VERSION ""

NS_ :

BS_:

BU_: SECU ES DCDC

BO_ 1536 NDCDCCtrl: 8 SECU
 SG_ BoostCoilOffRequested : 3|2@0+ (1,0) [0|3] "-" DCDC

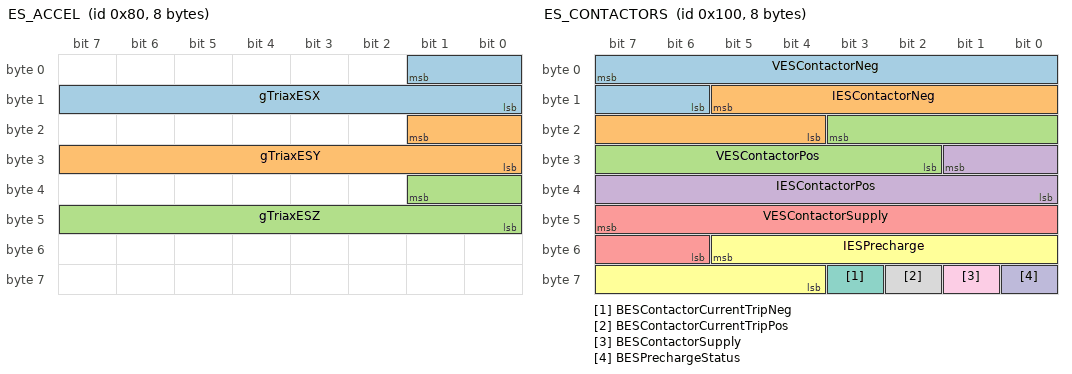
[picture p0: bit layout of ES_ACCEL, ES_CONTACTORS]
BO_ 128 ES_ACCEL: 8 ES
 SG_ gTriaxESX : 1|10@0- (0.015625,0) [-8|8] "G" SECU
 SG_ gTriaxESY : 17|10@0- (0.015625,0) [-8|8] "G" SECU
 SG_ gTriaxESZ : 33|10@0- (0.015625,0) [-8|8] "G" SECU

BO_ 256 ES_CONTACTORS: 8 ES
 SG_ VESContactorNeg : 7|10@0+ (1.58019822006473E-02,0) [0|16.1812297734628] "V" SECU
 SG_ IESContactorNeg : 13|10@0+ (1.220703125,0) [0|1250] "mA" SECU
 SG_ VESContactorPos : 19|10@0+ (1.58019822006473E-02,0) [0|16.1812297734628] "V" SECU
 SG_ IESContactorPos : 25|10@0+ (1.220703125,0) [0|1250] "mA" SECU
 SG_ VESContactorSupply : 47|10@0+ (1.52717752659574E-02,0) [0|15.6382978723404] "V" SECU
 SG_ IESPrecharge : 53|10@0+ (0.406901041666667,0) [0|416.666666666667] "mA" SECU
 SG_ BESContactorCurrentTripNeg : 59|1@0+ (1,0) [0|1] "-" SECU
 SG_ BESContactorCurrentTripPos : 58|1@0+ (1,0) [0|1] "-" SECU
 SG_ BESContactorSupply : 57|1@0+ (1,0) [0|1] "-" SECU
 SG_ BESPrechargeStatus : 56|1@0+ (1,0) [0|1] "-" SECU

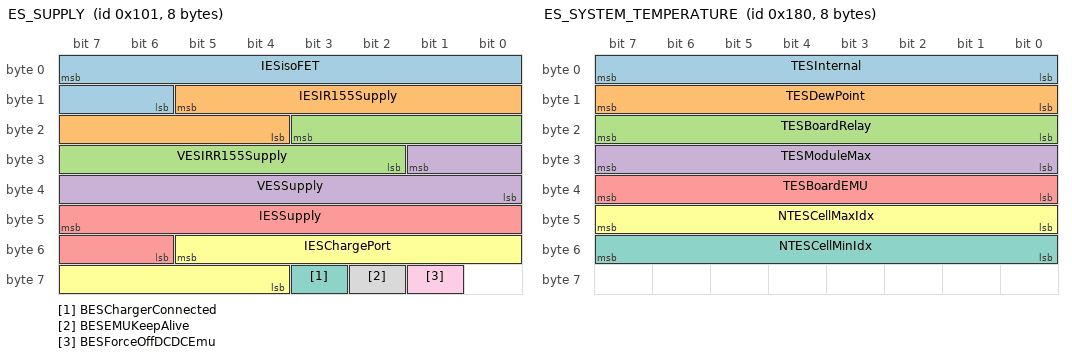
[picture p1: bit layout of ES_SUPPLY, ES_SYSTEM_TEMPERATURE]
BO_ 257 ES_SUPPLY: 8 ES
 SG_ IESisoFET : 7|10@0+ (0.406901041666667,0) [0|416.666666666667] "mA" SECU
 SG_ IESIR155Supply : 13|10@0+ (0.813802083333333,0) [0|833.333333333333] "mA" SECU
 SG_ VESIRR155Supply : 19|10@0+ (1.52717752659574E-02,0) [0|15.6382978723404] "V" SECU
 SG_ VESSupply : 25|10@0+ (1.52717752659574E-02,0) [0|15.6382978723404] "V" SECU
 SG_ IESSupply : 47|10@0+ (0.813802083333333,0) [0|833.333333333333] "mA" SECU
 SG_ IESChargePort : 53|10@0+ (0.406901041666667,0) [0|416.666666666667] "mA" SECU
 SG_ BESChargerConnected : 59|1@0+ (1,0) [0|1] "-" SECU
 SG_ BESEMUKeepAlive : 58|1@0+ (1,0) [0|1] "-" SECU
 SG_ BESForceOffDCDCEmu : 57|1@0+ (1,0) [0|1] "-" SECU

BO_ 384 ES_SYSTEM_TEMPERATURE: 8 ES
 SG_ TESInternal : 7|8@0+ (1,-40) [-40|210] "degreesC" SECU
 SG_ TESDewPoint : 15|8@0+ (1,-120) [-120|135] "degreesC" SECU
 SG_ TESBoardRelay : 23|8@0+ (1,-40) [-40|210] "degreesC" SECU
 SG_ TESModuleMax : 31|8@0+ (1,-40) [-40|210] "degreesC" SECU
 SG_ TESBoardEMU : 39|8@0+ (1,-40) [-40|210] "degreesC" SECU
 SG_ NTESCellMaxIdx : 47|8@0+ (1,0) [0|255] "-" SECU
 SG_ NTESCellMinIdx : 55|8@0+ (1,0) [0|255] "-" SECU

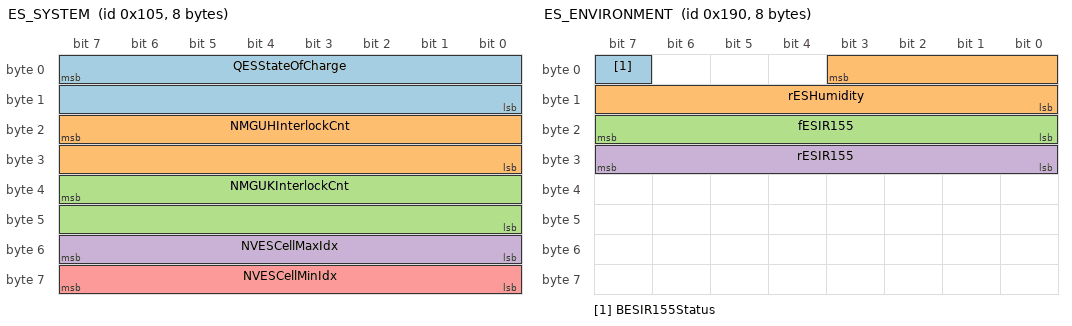
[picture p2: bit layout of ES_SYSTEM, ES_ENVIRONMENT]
BO_ 261 ES_SYSTEM: 8 ES
 SG_ QESStateOfCharge : 7|16@0- (1,0) [-30000|30000] "mAh" SECU
 SG_ NMGUHInterlockCnt : 23|16@0+ (1,0) [0|65535] "-" SECU
 SG_ NMGUKInterlockCnt : 39|16@0+ (1,0) [0|65535] "-" SECU
 SG_ NVESCellMaxIdx : 55|8@0+ (1,0) [0|255] "-" SECU
 SG_ NVESCellMinIdx : 63|8@0+ (1,0) [0|255] "-" SECU

BO_ 400 ES_ENVIRONMENT: 8 ES
 SG_ BESIR155Status : 7|1@0+ (1,0) [0|1] "-" SECU
 SG_ rESHumidity : 3|12@0+ (0.5,0) [0|100] "%" SECU
 SG_ fESIR155 : 23|8@0+ (1,0) [0|100] "Hz" SECU
 SG_ rESIR155 : 31|8@0+ (1,0) [0|100] "%" SECU

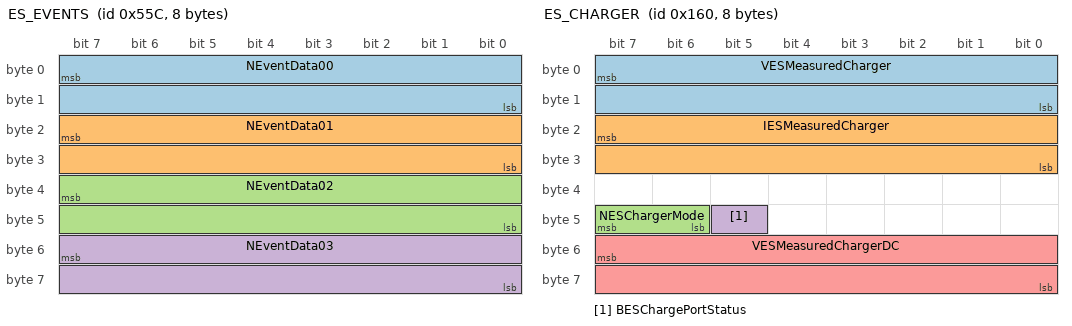
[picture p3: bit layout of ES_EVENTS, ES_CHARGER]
BO_ 1372 ES_EVENTS: 8 ES
 SG_ NEventData00 : 7|16@0+ (1,0) [0|65535] "-" SECU
 SG_ NEventData01 : 23|16@0+ (1,0) [0|65535] "-" SECU
 SG_ NEventData02 : 39|16@0+ (1,0) [0|65535] "-" SECU
 SG_ NEventData03 : 55|16@0+ (1,0) [0|65535] "-" SECU

BO_ 272 ES_STATUS: 8 ES
 SG_ muxEsStatus M : 7|8@0+ (1,0) [0|12] "-" SECU
 SG_ NESResetCount m0 : 15|8@0+ (1,0) [0|255] "-" SECU
 SG_ NESSerialNo m1 : 15|8@0+ (1,0) [0|255] "-" SECU
 SG_ NESCAN01BusState m2 : 15|2@0+ (1,0) [0|3] "-" SECU
 SG_ BQESStateOfChargeReset m3 : 15|1@0+ (1,0) [0|1] "-" SECU
 SG_ NESModuleIdxOpenWire m4 : 15|5@0+ (1,0) [0|20] "-" SECU
 SG_ NESModuleIdxComms m5 : 15|5@0+ (1,0) [0|20] "-" SECU
 SG_ NESModuleIdxFault m6 : 15|5@0+ (1,0) [0|20] "-" SECU
 SG_ NESCellsBalanced m7 : 15|8@0+ (1,0) [0|240] "-" SECU
 SG_ NESModuleADCStoppedCount m8 : 15|8@0+ (1,0) [0|255] "-" SECU
 SG_ NEMUSerialNumber m9 : 15|16@0+ (1,0) [0|65535] "-" SECU
 SG_ QESLastSOCReset m10 : 15|16@0- (1,0) [-30000|30000] "mAh" SECU
 SG_ QESLastBalance m11 : 15|16@0- (1,0) [-30000|30000] "mAh" SECU
 SG_ NESCAN02BusState m2 : 13|2@0+ (1,0) [0|3] "-" SECU
 SG_ BESEthernetConnected m3 : 12|1@0+ (1,0) [0|1] "-" SECU
 SG_ NESCAN03BusState m2 : 11|2@0+ (1,0) [0|3] "-" SECU
 SG_ NESCANChargerBusState m2 : 9|2@0+ (1,0) [0|3] "-" SECU
 SG_ NESCAN01BusOffCount m0 : 23|16@0+ (1,0) [0|65535] "-" SECU
 SG_ NESCAN02BusOffCount m1 : 23|16@0+ (1,0) [0|65535] "-" SECU
 SG_ NESCAN03BusOffCount m2 : 23|16@0+ (1,0) [0|65535] "-" SECU
 SG_ NESCANChargerBusOffCount m3 : 23|16@0+ (1,0) [0|65535] "-" SECU
 SG_ NESCANChargerTxMsgCount m4 : 23|16@0+ (1,0) [0|65535] "-" SECU
 SG_ NESCAN02RxMsgCount m5 : 23|16@0+ (1,0) [0|65535] "-" SECU
 SG_ NESCAN03TxMsgCount m6 : 23|16@0+ (1,0) [0|65535] "-" SECU
 SG_ NESOpenWire m7 : 23|16@0+ (1,0) [0|65535] "-" SECU
 SG_ NESResetReason m8 : 23|16@0+ (1,0) [0|65535] "-" SECU
 SG_ EESPrecharge m12 : 23|16@0+ (1,0) [0|65535] "J" SECU
 SG_ NESActiveResetCount m9 : 31|8@0+ (1,0) [0|255] "-" SECU
 SG_ NESCAN01ErrorCount m0 : 39|16@0+ (1,0) [0|65535] "-" SECU
 SG_ NESCAN02ErrorCount m1 : 39|16@0+ (1,0) [0|65535] "-" SECU
 SG_ NESCAN03ErrorCount m2 : 39|16@0+ (1,0) [0|65535] "-" SECU
 SG_ NESCANChargerErrorCount m3 : 39|16@0+ (1,0) [0|65535] "-" SECU
 SG_ NESCAN01RxMsgCount m4 : 39|16@0+ (1,0) [0|65535] "-" SECU
 SG_ NESCAN02TxMsgCount m5 : 39|16@0+ (1,0) [0|65535] "-" SECU
 SG_ NESModuleCommsErrors m7 : 39|16@0+ (1,0) [0|65535] "-" SECU
 SG_ NESSoftwareVersion m8 : 39|32@0+ (1,0) [0|4294967295] "-" SECU
 SG_ QESStateOfChargeOffset m9 : 39|16@0- (1,0) [-30000|30000] "mAh" SECU
 SG_ tESLastBalance m10 : 39|32@0+ (1,0) [0|4294967295] "s" SECU
 SG_ tESLastSOCReset m11 : 39|32@0+ (1,0) [0|4294967295] "s" SECU
 SG_ EESPrechargeMax m12 : 39|16@0+ (1,0) [0|65535] "J" SECU
 SG_ VESRef m0 : 55|16@0+ (0.0048828125,0) [0|5] "V" SECU
 SG_ NESEthernetTx m1 : 55|16@0+ (1,0) [0|65535] "-" SECU
 SG_ NESEthernetRx m2 : 55|16@0+ (1,0) [0|65535] "-" SECU
 SG_ NESCANChargerRxMsgCount m3 : 55|16@0+ (1,0) [0|65535] "-" SECU
 SG_ NESCAN01TxMsgCount m4 : 55|16@0+ (1,0) [0|65535] "-" SECU
 SG_ NESCAN03RxMsgCount m5 : 55|16@0+ (1,0) [0|65535] "-" SECU
 SG_ NESModuleFaultCounter m6 : 55|8@0+ (1,0) [0|255] "-" SECU
 SG_ NESCellsBalancing m7 : 55|8@0+ (1,0) [0|240] "-" SECU
 SG_ QESStateOfChargeIntegral m9 : 55|16@0- (1,0) [-30000|30000] "mAh" SECU
 SG_ VESPrechargeMin m12 : 55|16@0+ (0.036,0) [-1179.648|1179.63] "V" SECU
 SG_ NESModuleADCRangeCount m6 : 63|8@0+ (1,0) [0|255] "-" SECU
 SG_ NESModuleMismatchCount m7 : 63|8@0+ (1,0) [0|255] "-" SECU

BO_ 352 ES_CHARGER: 8 ES
 SG_ VESMeasuredCharger : 7|16@0- (0.036,0) [-1179.648|1179.63] "V" SECU
 SG_ IESMeasuredCharger : 23|16@0- (0.001,0) [0|10] "A" SECU
 SG_ NESChargerMode : 47|2@0+ (1,0) [0|3] "-" SECU
 SG_ BESChargePortStatus : 45|1@0+ (1,0) [0|1] "-" SECU
 SG_ VESMeasuredChargerDC : 55|16@0+ (0.02992,-980.41856) [-980.41856|980.38864] "V" SECU

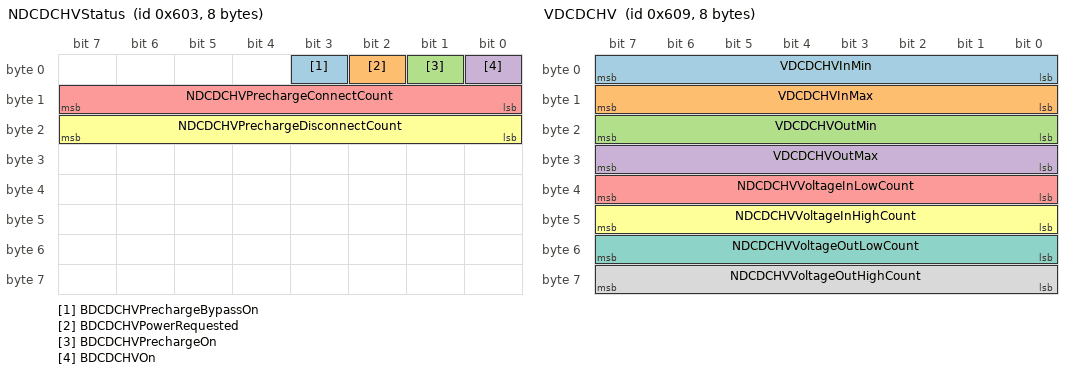
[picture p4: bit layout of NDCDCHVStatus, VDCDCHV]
BO_ 1539 NDCDCHVStatus: 8 DCDC
 SG_ BDCDCHVPrechargeBypassOn : 3|1@0+ (1,0) [0|1] "-" SECU
 SG_ BDCDCHVPowerRequested : 2|1@0+ (1,0) [0|1] "-" SECU
 SG_ BDCDCHVPrechargeOn : 1|1@0+ (1,0) [0|1] "-" SECU
 SG_ BDCDCHVOn : 0|1@0+ (1,0) [0|1] "-" SECU
 SG_ NDCDCHVPrechargeConnectCount : 15|8@0+ (1,0) [0|255] "-" SECU
 SG_ NDCDCHVPrechargeDisconnectCount : 23|8@0+ (1,0) [0|255] "-" SECU

BO_ 1537 NDCDCPLVStatus: 8 DCDC
 SG_ BDCDCPLVBackupBatteryChargerIdle : 7|1@0+ (1,0) [0|1] "-" SECU
 SG_ BDCDCPLVBackupBatteryChargerOn : 6|1@0+ (1,0) [0|1] "-" SECU
 SG_ BDCDCPLVEMUOutputOn : 5|1@0+ (1,0) [0|1] "-" SECU
 SG_ BDCDCPLVCoilOutputOn : 4|1@0+ (1,0) [0|1] "-" SECU
 SG_ BDCDCPLVBoostOutputOn : 3|1@0+ (1,0) [0|1] "-" SECU
 SG_ BDCDCPLVMainConverterOn : 2|1@0+ (1,0) [0|1] "-" ES,SECU
 SG_ BDCDCPLVUmbilicalAvailable : 1|1@0+ (1,0) [0|1] "-" SECU
 SG_ BDCDCPLVMainOutputOn : 0|1@0+ (1,0) [0|1] "-" SECU
 SG_ BDCDCPLVKeepAliveEMU : 15|1@0+ (1,0) [0|1] "-" SECU
 SG_ BDCDCPLVForceOffEMU : 14|1@0+ (1,0) [0|1] "-" SECU
 SG_ BDCDCPLVKeepAliveTAG : 13|1@0+ (1,0) [0|1] "-" SECU
 SG_ BDCDCPLVEnableSwitch : 12|1@0+ (1,0) [0|1] "-" SECU
 SG_ BDCDCPLVKeepAliveSLVC : 11|1@0+ (1,0) [0|1] "-" SECU
 SG_ BDCDCPLVKeepAliveHVC : 10|1@0+ (1,0) [0|1] "-" SECU
 SG_ BDCDCPLVEnableCommSLVC : 9|1@0+ (1,0) [0|1] "-" SECU
 SG_ BDCDCPLVEnableCommHVC : 8|1@0+ (1,0) [0|1] "-" SECU
 SG_ NDCDCPLVEnableSwitchFallCount : 23|4@0+ (1,0) [0|15] "-" SECU
 SG_ NDCDCPLVEnableSwitchRiseCount : 19|4@0+ (1,0) [0|15] "-" SECU
 SG_ NDCDCPLVKeepAliveTAGFallCount : 31|4@0+ (1,0) [0|15] "-" SECU
 SG_ NDCDCPLVKeepAliveTAGRiseCount : 27|4@0+ (1,0) [0|15] "-" SECU
 SG_ NDCDCPLVApplicationEntryCount : 39|8@0+ (1,0) [0|255] "-" SECU
 SG_ NDCDCPLVApplicationExitCount : 47|8@0+ (1,0) [0|255] "-" SECU

BO_ 1542 TDCDCHV: 8 DCDC
 SG_ TDCDCHVCPU : 7|8@0+ (1,0) [0|255] "degreesC" SECU
 SG_ TDCDCHVPCB : 15|8@0+ (1,0) [0|255] "degreesC" SECU

BO_ 1545 VDCDCHV: 8 DCDC
 SG_ VDCDCHVInMin : 7|8@0+ (3.9,0) [0|994.5] "V" SECU
 SG_ VDCDCHVInMax : 15|8@0+ (3.9,0) [0|994.5] "V" SECU
 SG_ VDCDCHVOutMin : 23|8@0+ (3,0) [0|765] "V" SECU
 SG_ VDCDCHVOutMax : 31|8@0+ (3,0) [0|765] "V" SECU
 SG_ NDCDCHVVoltageInLowCount : 39|8@0+ (1,0) [0|255] "-" SECU
 SG_ NDCDCHVVoltageInHighCount : 47|8@0+ (1,0) [0|255] "-" SECU
 SG_ NDCDCHVVoltageOutLowCount : 55|8@0+ (1,0) [0|255] "-" SECU
 SG_ NDCDCHVVoltageOutHighCount : 63|8@0+ (1,0) [0|255] "-" SECU

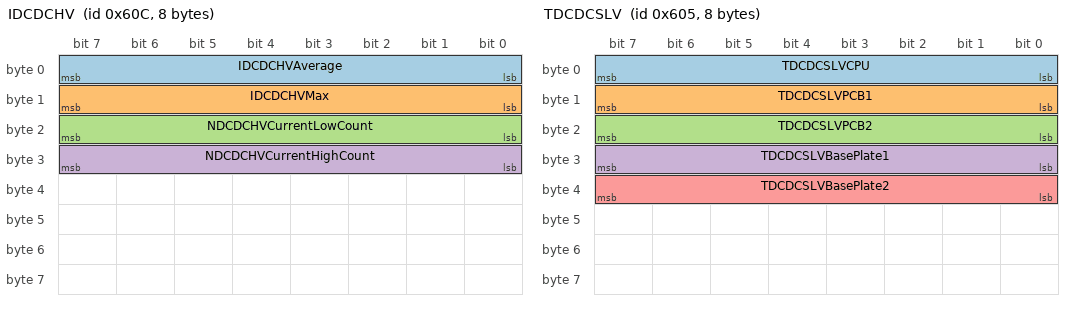
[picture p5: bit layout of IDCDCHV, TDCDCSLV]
BO_ 1548 IDCDCHV: 8 DCDC
 SG_ IDCDCHVAverage : 7|8@0+ (0.032,0) [0|8.16] "A" SECU
 SG_ IDCDCHVMax : 15|8@0+ (0.032,0) [0|8.16] "A" SECU
 SG_ NDCDCHVCurrentLowCount : 23|8@0+ (1,0) [0|255] "-" SECU
 SG_ NDCDCHVCurrentHighCount : 31|8@0+ (1,0) [0|255] "-" SECU

BO_ 1541 TDCDCSLV: 8 DCDC
 SG_ TDCDCSLVCPU : 7|8@0+ (1,0) [0|255] "degreesC" SECU
 SG_ TDCDCSLVPCB1 : 15|8@0+ (1,0) [0|255] "degreesC" SECU
 SG_ TDCDCSLVPCB2 : 23|8@0+ (1,0) [0|255] "degreesC" SECU
 SG_ TDCDCSLVBasePlate1 : 31|8@0+ (1,0) [0|255] "degreesC" SECU
 SG_ TDCDCSLVBasePlate2 : 39|8@0+ (1,0) [0|255] "degreesC" SECU

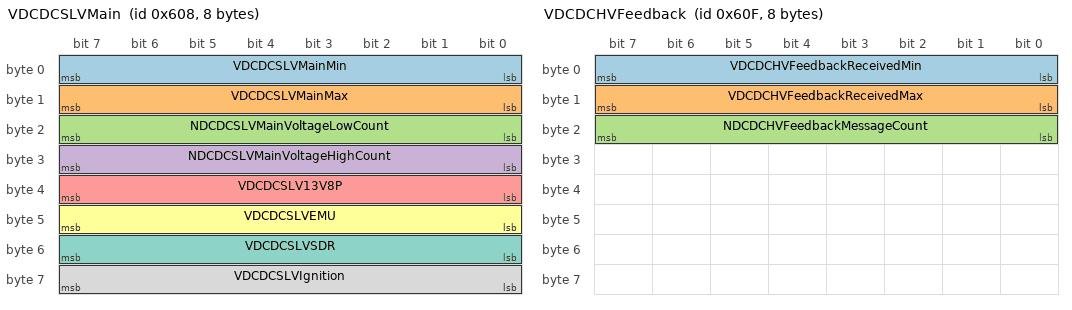
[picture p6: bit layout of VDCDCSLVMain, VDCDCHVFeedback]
BO_ 1544 VDCDCSLVMain: 8 DCDC
 SG_ VDCDCSLVMainMin : 7|8@0+ (0.075,0) [0|19.125] "V" SECU
 SG_ VDCDCSLVMainMax : 15|8@0+ (0.075,0) [0|19.125] "V" SECU
 SG_ NDCDCSLVMainVoltageLowCount : 23|8@0+ (1,0) [0|255] "-" SECU
 SG_ NDCDCSLVMainVoltageHighCount : 31|8@0+ (1,0) [0|255] "-" SECU
 SG_ VDCDCSLV13V8P : 39|8@0+ (0.075,0) [0|19.125] "V" SECU
 SG_ VDCDCSLVEMU : 47|8@0+ (0.075,0) [0|19.125] "V" SECU
 SG_ VDCDCSLVSDR : 55|8@0+ (0.075,0) [0|19.125] "V" SECU
 SG_ VDCDCSLVIgnition : 63|8@0+ (0.075,0) [0|19.125] "V" SECU

BO_ 1551 VDCDCHVFeedback: 8 DCDC
 SG_ VDCDCHVFeedbackReceivedMin : 7|8@0+ (0.234,0) [0|59.67] "V" SECU
 SG_ VDCDCHVFeedbackReceivedMax : 15|8@0+ (0.234,0) [0|59.67] "V" SECU
 SG_ NDCDCHVFeedbackMessageCount : 23|8@0+ (1,0) [0|255] "-" SECU

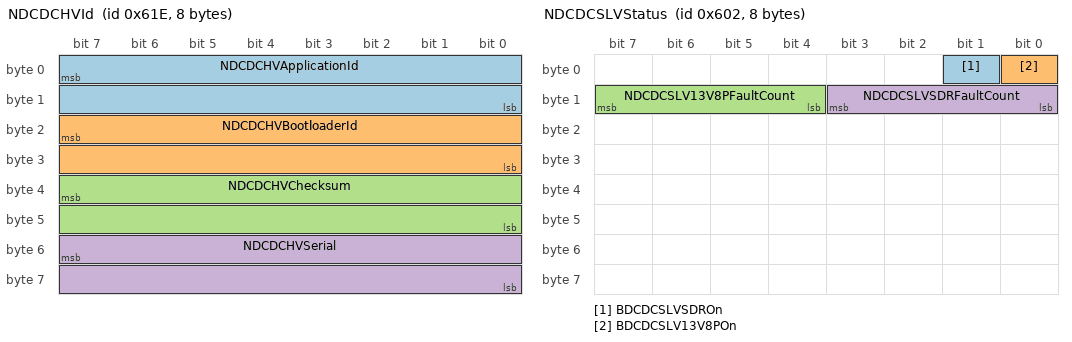
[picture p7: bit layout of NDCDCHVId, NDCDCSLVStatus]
BO_ 1566 NDCDCHVId: 8 DCDC
 SG_ NDCDCHVApplicationId : 7|16@0+ (1,0) [0|65535] "-" SECU
 SG_ NDCDCHVBootloaderId : 23|16@0+ (1,0) [0|65535] "-" SECU
 SG_ NDCDCHVChecksum : 39|16@0+ (1,0) [0|65535] "-" SECU
 SG_ NDCDCHVSerial : 55|16@0+ (1,0) [0|65535] "-" SECU

BO_ 1538 NDCDCSLVStatus: 8 DCDC
 SG_ BDCDCSLVSDROn : 1|1@0+ (1,0) [0|1] "-" SECU
 SG_ BDCDCSLV13V8POn : 0|1@0+ (1,0) [0|1] "-" SECU
 SG_ NDCDCSLV13V8PFaultCount : 15|4@0+ (1,0) [0|15] "-" SECU
 SG_ NDCDCSLVSDRFaultCount : 11|4@0+ (1,0) [0|15] "-" SECU

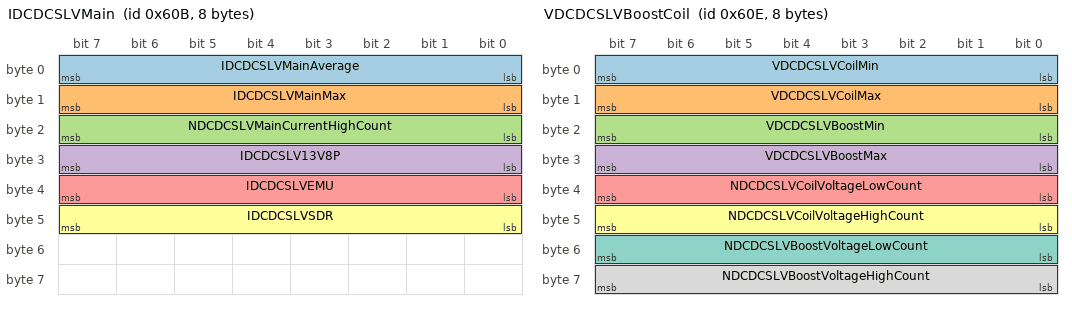
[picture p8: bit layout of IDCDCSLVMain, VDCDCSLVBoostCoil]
BO_ 1547 IDCDCSLVMain: 8 DCDC
 SG_ IDCDCSLVMainAverage : 7|8@0+ (0.334,0) [0|85.17] "A" SECU
 SG_ IDCDCSLVMainMax : 15|8@0+ (0.334,0) [0|85.17] "A" SECU
 SG_ NDCDCSLVMainCurrentHighCount : 23|8@0+ (1,0) [0|255] "-" SECU
 SG_ IDCDCSLV13V8P : 31|8@0+ (0.1,0) [0|25.5] "A" SECU
 SG_ IDCDCSLVEMU : 39|8@0+ (0.01567,0) [0|3.99585] "A" SECU
 SG_ IDCDCSLVSDR : 47|8@0+ (0.02745,0) [0|6.99975] "A" SECU

BO_ 1550 VDCDCSLVBoostCoil: 8 DCDC
 SG_ VDCDCSLVCoilMin : 7|8@0+ (0.234,0) [0|59.67] "V" SECU
 SG_ VDCDCSLVCoilMax : 15|8@0+ (0.234,0) [0|59.67] "V" SECU
 SG_ VDCDCSLVBoostMin : 23|8@0+ (0.441,0) [0|112.455] "V" SECU
 SG_ VDCDCSLVBoostMax : 31|8@0+ (0.441,0) [0|112.455] "V" SECU
 SG_ NDCDCSLVCoilVoltageLowCount : 39|8@0+ (1,0) [0|255] "-" SECU
 SG_ NDCDCSLVCoilVoltageHighCount : 47|8@0+ (1,0) [0|255] "-" SECU
 SG_ NDCDCSLVBoostVoltageLowCount : 55|8@0+ (1,0) [0|255] "-" SECU
 SG_ NDCDCSLVBoostVoltageHighCount : 63|8@0+ (1,0) [0|255] "-" SECU

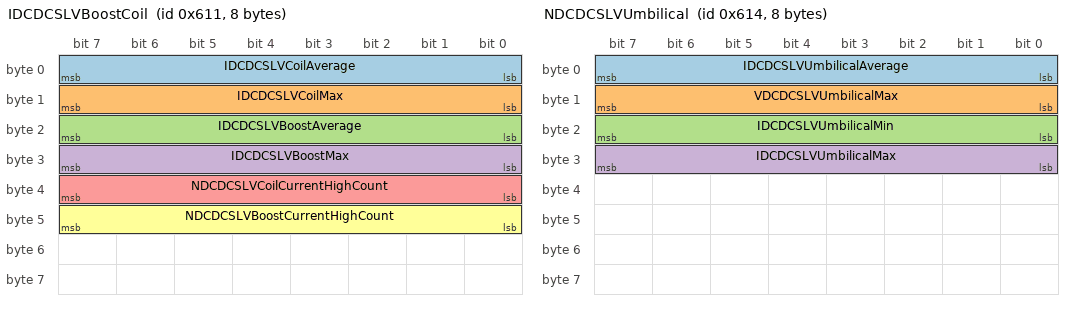
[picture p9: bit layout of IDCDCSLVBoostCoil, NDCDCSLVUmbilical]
BO_ 1553 IDCDCSLVBoostCoil: 8 DCDC
 SG_ IDCDCSLVCoilAverage : 7|8@0+ (0.095,0) [0|24.225] "A" SECU
 SG_ IDCDCSLVCoilMax : 15|8@0+ (0.095,0) [0|24.225] "A" SECU
 SG_ IDCDCSLVBoostAverage : 23|8@0+ (0.02745,0) [0|6.99975] "A" SECU
 SG_ IDCDCSLVBoostMax : 31|8@0+ (0.02745,0) [0|6.99975] "A" SECU
 SG_ NDCDCSLVCoilCurrentHighCount : 39|8@0+ (1,0) [0|255] "-" SECU
 SG_ NDCDCSLVBoostCurrentHighCount : 47|8@0+ (1,0) [0|255] "-" SECU

BO_ 1556 NDCDCSLVUmbilical: 8 DCDC
 SG_ IDCDCSLVUmbilicalAverage : 7|8@0+ (0.075,0) [0|19.125] "V" SECU
 SG_ VDCDCSLVUmbilicalMax : 15|8@0+ (0.075,0) [0|19.125] "V" SECU
 SG_ IDCDCSLVUmbilicalMin : 23|8@0+ (0.118,0) [0|30.09] "A" SECU
 SG_ IDCDCSLVUmbilicalMax : 31|8@0+ (0.118,0) [0|30.09] "A" SECU

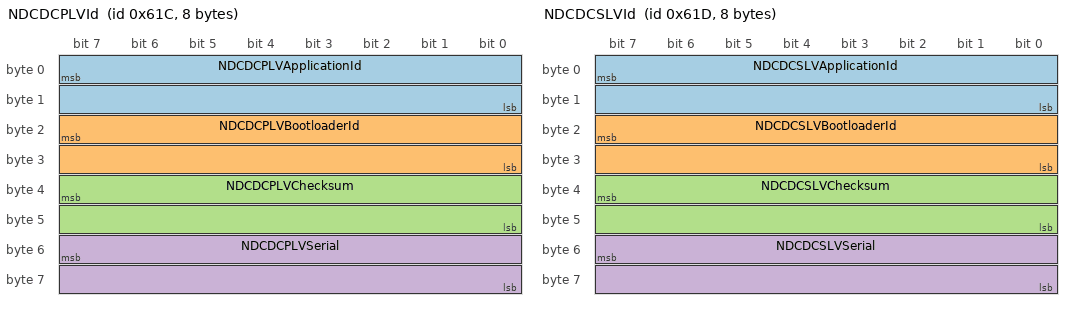
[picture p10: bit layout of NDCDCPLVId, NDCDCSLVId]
BO_ 1564 NDCDCPLVId: 8 DCDC
 SG_ NDCDCPLVApplicationId : 7|16@0+ (1,0) [0|65535] "-" SECU
 SG_ NDCDCPLVBootloaderId : 23|16@0+ (1,0) [0|65535] "-" SECU
 SG_ NDCDCPLVChecksum : 39|16@0+ (1,0) [0|65535] "-" SECU
 SG_ NDCDCPLVSerial : 55|16@0+ (1,0) [0|65535] "-" SECU

BO_ 1565 NDCDCSLVId: 8 DCDC
 SG_ NDCDCSLVApplicationId : 7|16@0+ (1,0) [0|65535] "-" SECU
 SG_ NDCDCSLVBootloaderId : 23|16@0+ (1,0) [0|65535] "-" SECU
 SG_ NDCDCSLVChecksum : 39|16@0+ (1,0) [0|65535] "-" SECU
 SG_ NDCDCSLVSerial : 55|16@0+ (1,0) [0|65535] "-" SECU

BO_ 1543 VDCDCPLV: 8 DCDC
 SG_ VDCDCPLVBackupBattery : 7|8@0+ (0.02588,0) [0|6.5994] "V" SECU

BO_ 1540 IDCDCPLVBuckLoadUnbalance: 8 DCDC
 SG_ IDCDCPLVBuckLoadUnbalance : 7|8@0+ (0.161,0) [0|41.055] "A" SECU

CM_ SG_ 128 gTriaxESX "ES internal triax X axis acceleration";
CM_ SG_ 128 gTriaxESY "ES internal triax Y axis acceleration";
CM_ SG_ 128 gTriaxESZ "ES internal triax Z axis acceleration";
CM_ SG_ 256 VESContactorNeg "Voltage across the negative contactor coil voltage";
CM_ SG_ 256 IESContactorNeg "Negative contactor coil current";
CM_ SG_ 256 VESContactorPos "Voltage across the positive contactor coil voltage";
CM_ SG_ 256 IESContactorPos "Positive contactor coil current";
CM_ SG_ 256 VESContactorSupply "ES contactor supply voltage";
CM_ SG_ 256 IESPrecharge "Precharge relay coil current";
CM_ SG_ 256 BESContactorCurrentTripNeg "Negative contactor drive circuit in error flag";
CM_ SG_ 256 BESContactorCurrentTripPos "Positive contactor drive circuit in error flag";
CM_ SG_ 256 BESContactorSupply "Set when the VESContactorSupply is present";
CM_ SG_ 256 BESPrechargeStatus "Status of the pre-charge relay";
CM_ SG_ 257 IESisoFET "IsoFET drive current";
CM_ SG_ 257 IESIR155Supply "Bender supply current";
CM_ SG_ 257 VESIRR155Supply "12V supply voltage to the IR155";
CM_ SG_ 257 VESSupply "Energy store 12V supply voltage";
CM_ SG_ 257 IESSupply "ES 12V supply current";
CM_ SG_ 257 IESChargePort "Charge port relay coil current";
CM_ SG_ 257 BESChargerConnected "Set to indicate that the off-car charger is connected to the charger CAN port";
CM_ SG_ 257 BESEMUKeepAlive "Flag indicating that the EMU wishes to be kept alive in P0";
CM_ SG_ 257 BESForceOffDCDCEmu "Command to force the HV supply to the DC-DC converter off";
CM_ SG_ 384 TESInternal "Ambient temperature inside the energy store";
CM_ SG_ 384 TESDewPoint "Measured dew point within the ES";
CM_ SG_ 384 TESBoardRelay "Board temperature of the EMU HV relay board";
CM_ SG_ 384 TESModuleMax "Max ES module board temperature";
CM_ SG_ 384 TESBoardEMU "Board temperature of the EMU";
CM_ SG_ 384 NTESCellMaxIdx "Index of the highest cell temperature in the pack";
CM_ SG_ 384 NTESCellMinIdx "Index of the lowest cell temperature in the pack";
CM_ SG_ 261 QESStateOfCharge "ES state of discharge in mAh";
CM_ SG_ 261 NMGUHInterlockCnt "Count of the transitions in the ES MGU-H HVIL input";
CM_ SG_ 261 NMGUKInterlockCnt "Count of the transitions in the ES MGU-K HVIL input";
CM_ SG_ 261 NVESCellMaxIdx "Index of the cell with the highest voltage in the pack";
CM_ SG_ 261 NVESCellMinIdx "Index of the cell with the lowest voltage in the pack";
CM_ SG_ 400 BESIR155Status "Fault status of the Bender IR155 board";
CM_ SG_ 400 rESHumidity "Relative humidity within the ES";
CM_ SG_ 400 fESIR155 "Measured output frequency of the Bender IR155 board";
CM_ SG_ 400 rESIR155 "Measured output duty cycle of the Bender IR155 board";
CM_ SG_ 1372 NEventData00 "Event data word 0";
CM_ SG_ 1372 NEventData01 "Event data word 1";
CM_ SG_ 1372 NEventData02 "Event data word 2";
CM_ SG_ 1372 NEventData03 "Event data word 3";
CM_ SG_ 272 NESResetCount "Number of EMU processor resets";
CM_ SG_ 272 NESCAN01BusOffCount "ES CAN bus 01 bus off count";
CM_ SG_ 272 NESCAN01ErrorCount "ES CAN bus 01 error count";
CM_ SG_ 272 VESRef "2.5V reference voltage on the EMU board";
CM_ SG_ 272 NESSerialNo "ES Serial number";
CM_ SG_ 272 NESCAN02BusOffCount "ES CAN bus 02 bus off count";
CM_ SG_ 272 NESCAN02ErrorCount "ES CAN bus 02 error count";
CM_ SG_ 272 NESEthernetTx "Ethernet Frames Transmitted OK Counter";
CM_ SG_ 272 NESCAN01BusState "ES CAN bus 01 bus state (Active, Passive, Off)";
CM_ SG_ 272 NESCAN02BusState "ES CAN bus 02 bus state (Active, Passive, Off)";
CM_ SG_ 272 NESCAN03BusState "ES CAN bus 03 bus state (Active, Passive, Off)";
CM_ SG_ 272 NESCANChargerBusState "ES charge CAN bus state (Active, Passive, Off)";
CM_ SG_ 272 NESCAN03BusOffCount "ES CAN bus 03 bus off count";
CM_ SG_ 272 NESCAN03ErrorCount "ES CAN bus 03 error count";
CM_ SG_ 272 NESEthernetRx "Ethernet Frames Received OK Counter";
CM_ SG_ 272 BQESStateOfChargeReset "Flag indicating that the SOC has been reset at startup";
CM_ SG_ 272 BESEthernetConnected "Status of the Ethernet connection";
CM_ SG_ 272 NESCANChargerBusOffCount "ES charger CAN bus off count";
CM_ SG_ 272 NESCANChargerErrorCount "ES charger CAN bus error count";
CM_ SG_ 272 NESCANChargerRxMsgCount "ES charge CAN bus received message count";
CM_ SG_ 272 NESModuleIdxOpenWire "Index of the module with the most open wire counts";
CM_ SG_ 272 NESCANChargerTxMsgCount "ES charger CAN bus transmitted message count";
CM_ SG_ 272 NESCAN01RxMsgCount "ES CAN bus 01 received message count";
CM_ SG_ 272 NESCAN01TxMsgCount "ES CAN bus 01 transmitted message count";
CM_ SG_ 272 NESModuleIdxComms "Index of the module with the most comms errors";
CM_ SG_ 272 NESCAN02RxMsgCount "ES CAN bus 02 received message count";
CM_ SG_ 272 NESCAN02TxMsgCount "ES CAN bus 02 transmitted message count";
CM_ SG_ 272 NESCAN03RxMsgCount "ES CAN bus 03 received message count";
CM_ SG_ 272 NESModuleIdxFault "Index of the module with the most self test errors";
CM_ SG_ 272 NESCAN03TxMsgCount "ES CAN bus 03 transmitted message count";
CM_ SG_ 272 NESModuleFaultCounter "Total number of self test failures";
CM_ SG_ 272 NESModuleADCRangeCount "Number of mismatches ADC range errors";
CM_ SG_ 272 NESCellsBalanced "Number of cell that are balanced";
CM_ SG_ 272 NESOpenWire "Count of the number of open wire detections";
CM_ SG_ 272 NESModuleCommsErrors "Total number of invalid communications";
CM_ SG_ 272 NESCellsBalancing "Number of cell being balanced";
CM_ SG_ 272 NESModuleMismatchCount "Number of mismatches between module voltage and the sum of the cell voltages";
CM_ SG_ 272 NESModuleADCStoppedCount "Number of times the ADC has failed to start";
CM_ SG_ 272 NESResetReason "Contents of the EMU processor reset register at the last power up";
CM_ SG_ 272 NESSoftwareVersion "EMU software build stamp";
CM_ SG_ 272 NEMUSerialNumber "EMU serial number";
CM_ SG_ 272 NESActiveResetCount "Number of times the EMU has reset while the contactors are closed";
CM_ SG_ 272 QESStateOfChargeOffset "ES state of discharge offset";
CM_ SG_ 272 QESStateOfChargeIntegral "ES state of discharge integral";
CM_ SG_ 272 QESLastSOCReset "SOC offset applied at the last SOC reset";
CM_ SG_ 272 tESLastBalance "Timestamp of the last ES balancing operation";
CM_ SG_ 272 QESLastBalance "SOC inbalance of ES during last balancing operation";
CM_ SG_ 272 tESLastSOCReset "Timestamp of the last ES SOC reset ";
CM_ SG_ 272 EESPrecharge "Energy dissipated in the precharge circuit during the last activation";
CM_ SG_ 272 EESPrechargeMax "Max energy dissipated in the precharge circuit";
CM_ SG_ 272 VESPrechargeMin "Minimum ES voltage measured during precharge";
CM_ SG_ 352 VESMeasuredCharger "Energy store voltage as measured by the off-car charger";
CM_ SG_ 352 IESMeasuredCharger "Energy store current as measured by the off-car charger";
CM_ SG_ 352 NESChargerMode "Off-car charger mode (0 off, 1 constant voltage, 2 constant current, 3 discharger)";
CM_ SG_ 352 BESChargePortStatus "Status of the charge port relay";
CM_ SG_ 352 VESMeasuredChargerDC "Secondary energy store voltage as measured by the plug in charger";
CM_ SG_ 1539 BDCDCHVPrechargeBypassOn "Indicates that the precharge bypass transistor is enabled";
CM_ SG_ 1539 BDCDCHVPowerRequested "Indicates that high-voltage side power has been requested";
CM_ SG_ 1539 BDCDCHVPrechargeOn "Indicates that the precharge auxiliary supply is enabled";
CM_ SG_ 1539 BDCDCHVOn "While the high-voltage side is operating this bit will keep switching between high and low";
CM_ SG_ 1539 NDCDCHVPrechargeConnectCount "Counts how many times the precharge circuit has been enabled by the high-voltage controller";
CM_ SG_ 1539 NDCDCHVPrechargeDisconnectCount "Counts how many times the precharge circuit has been disabled by the high-voltage controller";
CM_ SG_ 1537 BDCDCPLVBackupBatteryChargerIdle "Reflects whether the backup battery charger is idle";
CM_ SG_ 1537 BDCDCPLVBackupBatteryChargerOn "Reflects whether the backup battery charger is enabled";
CM_ SG_ 1537 BDCDCPLVEMUOutputOn "State of the EMU output";
CM_ SG_ 1537 BDCDCPLVCoilOutputOn "Reflects whether the Coil output is established";
CM_ SG_ 1537 BDCDCPLVBoostOutputOn "Reflects whether the Boost output is established";
CM_ SG_ 1537 BDCDCPLVMainConverterOn "Reflects whether the main converter (3-phase Buck) is providing power to the main output";
CM_ SG_ 1537 BDCDCPLVUmbilicalAvailable "Reflects whether the umbilical supply is detected by the DCDC";
CM_ SG_ 1537 BDCDCPLVMainOutputOn "Reflects whether the main output is providing power";
CM_ SG_ 1537 BDCDCPLVKeepAliveEMU "Reflects whether the EMU Keep Alive is enabled";
CM_ SG_ 1537 BDCDCPLVForceOffEMU "Reflects whether the EMU Force Off is enabled";
CM_ SG_ 1537 BDCDCPLVKeepAliveTAG "Reflects the state of the Keep-Alive signal received from the TAG";
CM_ SG_ 1537 BDCDCPLVEnableSwitch "Reflects whether the P0/P1 switch is activated";
CM_ SG_ 1537 BDCDCPLVKeepAliveSLVC "Reflects the state of the internal Keep-Alive signal received from the SLV controller";
CM_ SG_ 1537 BDCDCPLVKeepAliveHVC "Reflects the state of the internal Keep-Alive signal received from the HV controller";
CM_ SG_ 1537 BDCDCPLVEnableCommSLVC "Reflects the state of the internal Enable signal sent to the SLV controller";
CM_ SG_ 1537 BDCDCPLVEnableCommHVC "Reflects the state of the internal Enable signal sent to the HV controller";
CM_ SG_ 1537 NDCDCPLVEnableSwitchFallCount "Number of rising edges on the P0/P1 switch signal";
CM_ SG_ 1537 NDCDCPLVEnableSwitchRiseCount "Number of falling edges on the P0/P1 switch signal";
CM_ SG_ 1537 NDCDCPLVKeepAliveTAGFallCount "Number of rising edges on the Keep-Alive signal received from the TAG";
CM_ SG_ 1537 NDCDCPLVKeepAliveTAGRiseCount "Number of falling edges on the Keep-Alive signal received from the TAG";
CM_ SG_ 1537 NDCDCPLVApplicationEntryCount "Reflects how many times the PLV controller went through its application entry point";
CM_ SG_ 1537 NDCDCPLVApplicationExitCount "Reflects how many times the PLV controller went through its application exit point";
CM_ SG_ 1542 TDCDCHVCPU "CPU temperature on the high-voltage side";
CM_ SG_ 1542 TDCDCHVPCB "PCB temperature on the high-voltage side";
CM_ SG_ 1545 VDCDCHVInMin "Lowest value of the input voltage during the last interval";
CM_ SG_ 1545 VDCDCHVInMax "Highest value of the input voltage during the last interval";
CM_ SG_ 1545 VDCDCHVOutMin "Lowest value of the Buck output voltage during the last interval";
CM_ SG_ 1545 VDCDCHVOutMax "Highest value of the Buck output voltage during the last interval";
CM_ SG_ 1545 NDCDCHVVoltageInLowCount "Number of samples below the lower bound (550V) of the nominal range for the Buck input voltage during the last interval";
CM_ SG_ 1545 NDCDCHVVoltageInHighCount "Number of samples above the upper bound (900V) of the nominal range for the Buck input voltage during the last interval";
CM_ SG_ 1545 NDCDCHVVoltageOutLowCount "Number of samples below the lower bound (100V) of the nominal range for the Buck output voltage during the last interval";
CM_ SG_ 1545 NDCDCHVVoltageOutHighCount "Number of samples above the upper bound (550V) of the nominal range for the Buck output voltage during the last interval";
CM_ SG_ 1548 IDCDCHVAverage "Average value of the Buck current during the last interval";
CM_ SG_ 1548 IDCDCHVMax "Highest value of the Buck current during the last interval";
CM_ SG_ 1548 NDCDCHVCurrentLowCount "Number of samples below the lower bound (1A) of the nominal range of the Buck output current during the last interval";
CM_ SG_ 1548 NDCDCHVCurrentHighCount "Number of samples above the upper bound (9A) of the nominal range of the Buck output current during the last interval";
CM_ SG_ 1541 TDCDCSLVCPU "CPU temperature on the secondary low-voltage side controller";
CM_ SG_ 1541 TDCDCSLVPCB1 "PCB temperature on the low-voltage side (sensor 1)";
CM_ SG_ 1541 TDCDCSLVPCB2 "PCB temperature on the low-voltage side (sensor 2)";
CM_ SG_ 1541 TDCDCSLVBasePlate1 "Base plate temperature (sensor 1)";
CM_ SG_ 1541 TDCDCSLVBasePlate2 "Base plate temperature (sensor 2)";
CM_ SG_ 1544 VDCDCSLVMainMin "Lowest value of the Main output voltage during the last interval";
CM_ SG_ 1544 VDCDCSLVMainMax "Highest value of the Main output voltage during the last interval";
CM_ SG_ 1544 NDCDCSLVMainVoltageLowCount "Number of samples below the lower bound (12V) of the nominal range for the Main output voltage during the last interval";
CM_ SG_ 1544 NDCDCSLVMainVoltageHighCount "Number of samples above the upper bound (15V) of the nominal range for the Main output voltage during the last interval";
CM_ SG_ 1544 VDCDCSLV13V8P "Voltage of the 13V8P output";
CM_ SG_ 1544 VDCDCSLVEMU "Voltage of the EMU output";
CM_ SG_ 1544 VDCDCSLVSDR "Voltage of the SDR output";
CM_ SG_ 1544 VDCDCSLVIgnition "Voltage of the Ignition Drive output";
CM_ SG_ 1551 VDCDCHVFeedbackReceivedMin "Lowest feedback voltage value received during the last interval";
CM_ SG_ 1551 VDCDCHVFeedbackReceivedMax "Highest feedback voltage value received during the last interval";
CM_ SG_ 1551 NDCDCHVFeedbackMessageCount "Number of valid feedback voltage values received during the last interval";
CM_ SG_ 1566 NDCDCHVApplicationId "Version number of the high-voltage side software";
CM_ SG_ 1566 NDCDCHVBootloaderId "Version number of the high-voltage side bootloader";
CM_ SG_ 1566 NDCDCHVChecksum "Expected checksum for the high-voltage side software";
CM_ SG_ 1566 NDCDCHVSerial "Serial number registered in the high-voltage side controller";
CM_ SG_ 1538 BDCDCSLVSDROn "State of the SDR output";
CM_ SG_ 1538 BDCDCSLV13V8POn "State of the 13V8P output";
CM_ SG_ 1538 NDCDCSLV13V8PFaultCount "Number of faults detected on the 13V8P output";
CM_ SG_ 1538 NDCDCSLVSDRFaultCount "Number of faults detected on the SDRoutput";
CM_ SG_ 1547 IDCDCSLVMainAverage "Average value of the current through the Main output during the last interval";
CM_ SG_ 1547 IDCDCSLVMainMax "Highest value of the current through the Main output during the last interval";
CM_ SG_ 1547 NDCDCSLVMainCurrentHighCount "Number of samples above the upper bound (50A) of the nominal range of current for the Main output during the last interval";
CM_ SG_ 1547 IDCDCSLV13V8P "Current through the 13V8P output";
CM_ SG_ 1547 IDCDCSLVEMU "Current through the EMU output";
CM_ SG_ 1547 IDCDCSLVSDR "Current through the SDR output";
CM_ SG_ 1550 VDCDCSLVCoilMin "Lowest value of the Coil output voltage during the last interval";
CM_ SG_ 1550 VDCDCSLVCoilMax "Highest value of the Coil output voltage during the last interval";
CM_ SG_ 1550 VDCDCSLVBoostMin "Lowest value of the Boost output voltage during the last interval";
CM_ SG_ 1550 VDCDCSLVBoostMax "Highest value of the Boost output voltage during the last interval";
CM_ SG_ 1550 NDCDCSLVCoilVoltageLowCount "Number of samples below the lower bound (42V) of the nominal range for the Boost output voltage during the last interval";
CM_ SG_ 1550 NDCDCSLVCoilVoltageHighCount "Number of samples above the upper bound (54V) of the nominal range for the Boost output voltage during the last interval";
CM_ SG_ 1550 NDCDCSLVBoostVoltageLowCount "Number of samples below the lower bound (60V) of the nominal range for the Boost output voltage during the last interval";
CM_ SG_ 1550 NDCDCSLVBoostVoltageHighCount "Number of samples above the upper bound (70V) of the nominal range for the Boost output voltage during the last interval";
CM_ SG_ 1553 IDCDCSLVCoilAverage "Lowest value of the current through the Coil output during the last interval";
CM_ SG_ 1553 IDCDCSLVCoilMax "Highest value of the current through the Coil output during the last interval";
CM_ SG_ 1553 IDCDCSLVBoostAverage "Average value of the current through the Boost output during the last interval";
CM_ SG_ 1553 IDCDCSLVBoostMax "Highest value of the current through the Boost output during the last interval";
CM_ SG_ 1553 NDCDCSLVCoilCurrentHighCount "Number of samples above the upper bound (10A) of the nominal range of current for the Coil output during the last interval";
CM_ SG_ 1553 NDCDCSLVBoostCurrentHighCount "Number of samples above the upper bound (3A) of the nominal range of current for the Boost output during the last interval";
CM_ SG_ 1556 IDCDCSLVUmbilicalAverage "Average value of the current provided by the umbilical supply during the last interval";
CM_ SG_ 1556 VDCDCSLVUmbilicalMax "Highest value of the umbilical supply voltage during the last interval";
CM_ SG_ 1556 IDCDCSLVUmbilicalMin "Lowest value of the current provided by the umbilical supply during the last interval";
CM_ SG_ 1556 IDCDCSLVUmbilicalMax "Highest value of the current provided by the umbilical supply during the last interval";
CM_ SG_ 1564 NDCDCPLVApplicationId "Version number of the primary low-voltage side software";
CM_ SG_ 1564 NDCDCPLVBootloaderId "Version number of the primary low-voltage side bootloader";
CM_ SG_ 1564 NDCDCPLVChecksum "Expected checksum for the primary low-voltage side software";
CM_ SG_ 1564 NDCDCPLVSerial "Serial number registered in the primary low-voltage side controller";
CM_ SG_ 1565 NDCDCSLVApplicationId "Version number of the secondary low-voltage side software";
CM_ SG_ 1565 NDCDCSLVBootloaderId "Version number of the secondary low-voltage side bootloader";
CM_ SG_ 1565 NDCDCSLVChecksum "Expected checksum for the secondary low-voltage side software";
CM_ SG_ 1565 NDCDCSLVSerial "Serial number registered in the secondary low-voltage side controller";
CM_ SG_ 1543 VDCDCPLVBackupBattery "Voltage measured on the backup battery of the DCDC";
CM_ SG_ 1540 IDCDCPLVBuckLoadUnbalance "Greatest difference in current provided amongst the 3 phases of the main converter";
BA_DEF_ BO_  "GenMsgCycleTime" INT 1 1001;
BA_DEF_  "BusType" STRING ;
BA_DEF_DEF_  "GenMsgCycleTime" 1000;
BA_DEF_DEF_  "BusType" "CAN";
BA_ "GenMsgCycleTime" BO_ 128 10;
BA_ "GenMsgCycleTime" BO_ 256 100;
BA_ "GenMsgCycleTime" BO_ 257 100;
BA_ "GenMsgCycleTime" BO_ 261 100;
BA_ "GenMsgCycleTime" BO_ 1372 500;
BA_ "GenMsgCycleTime" BO_ 272 100;
BA_ "GenMsgCycleTime" BO_ 352 100;
BA_ "GenMsgCycleTime" BO_ 1539 5;
BA_ "GenMsgCycleTime" BO_ 1537 5;
BA_ "GenMsgCycleTime" BO_ 1542 200;
BA_ "GenMsgCycleTime" BO_ 1545 5;
BA_ "GenMsgCycleTime" BO_ 1548 5;
BA_ "GenMsgCycleTime" BO_ 1541 200;
BA_ "GenMsgCycleTime" BO_ 1544 5;
BA_ "GenMsgCycleTime" BO_ 1551 10;
BA_ "GenMsgCycleTime" BO_ 1538 5;
BA_ "GenMsgCycleTime" BO_ 1547 5;
BA_ "GenMsgCycleTime" BO_ 1550 20;
BA_ "GenMsgCycleTime" BO_ 1553 20;
BA_ "GenMsgCycleTime" BO_ 1556 20;
